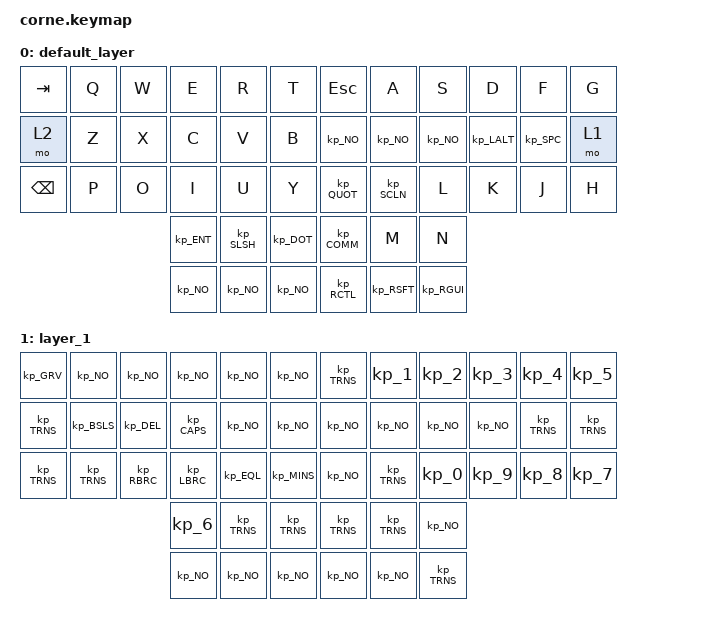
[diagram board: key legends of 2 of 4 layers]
/*
 * Copyright (c) 2020 The ZMK Contributors
 *
 * SPDX-License-Identifier: MIT
 */

#include <behaviors.dtsi>
#include <dt-bindings/zmk/keys.h>
#include <dt-bindings/zmk/bt.h>

/ {
    keymap {
        compatible = "zmk,keymap";

        default_layer {
            bindings = <
                // Layer 0
                &kp TAB &kp Q &kp W &kp E &kp R &kp T      &kp ESC &kp A &kp S &kp D &kp F &kp G
                &mo 2 &kp Z &kp X &kp C &kp V &kp B         &kp_NO &kp_NO &kp_NO &kp_LALT &kp_SPC &mo 1
                &kp BSPC &kp P &kp O &kp I &kp U &kp Y     &kp_QUOT &kp_SCLN &kp L &kp K &kp J &kp H
                &kp_ENT &kp_SLSH &kp_DOT &kp_COMM &kp M &kp N
                &kp_NO &kp_NO &kp_NO &kp_RCTL &kp_RSFT &kp_RGUI
            >;
        };

        layer_1 {
            bindings = <
                // Layer 1
                &kp_GRV &kp_NO &kp_NO &kp_NO &kp_NO &kp_NO
                &kp_TRNS &kp_1 &kp_2 &kp_3 &kp_4 &kp_5
                &kp_TRNS &kp_BSLS &kp_DEL &kp_CAPS &kp_NO &kp_NO
                &kp_NO &kp_NO &kp_NO &kp_NO &kp_TRNS &kp_TRNS
                &kp_TRNS &kp_TRNS &kp_RBRC &kp_LBRC &kp_EQL &kp_MINS
                &kp_NO &kp_TRNS &kp_0 &kp_9 &kp_8 &kp_7
                &kp_6 &kp_TRNS &kp_TRNS &kp_TRNS &kp_TRNS &kp_NO
                &kp_NO &kp_NO &kp_NO &kp_NO &kp_NO &kp_TRNS
            >;
        };

        layer_2 {
            bindings = <
                // Layer 2
                &kp_NO &kp_NO &kp_NO &kp_NO &kp_NO &kp_NO
                &kp_NO &kp_F5 &kp_F6 &kp_F7 &kp_F8 &kp_NO
                &kp_NO &kp_F9 &kp_F10 &kp_F11 &kp_F12 &kp_NO
                &kp_NO &kp_NO &kp_NO &kp_NO &kp_NO &kp_TRNS
                &kp_TRNS &kp_TRNS &kp_HOME &kp_PGUP &kp_NO &kp_NO
                &kp_NO &kp_NO &kp_NO &kp_NO &kp_NO &kp_NO
                &kp_RGHT &kp_UP &kp_DOWN &kp_LEFT &kp_END &kp_F4
                &kp_F3 &kp_F2 &kp_F1 &kp_PGDN &kp_NO &kp_NO
                &kp_NO &kp_TRNS &kp_TRNS &kp_TRNS
            >;
        };

        layer_3 {
            bindings = <
                // Layer 3 (media)
                &kp_NO &kp_NO &kp_NO &kp_NO &kp_NO &kp_NO
                &kp_NO &kp_NO &kp_NO &kp_NO &kp_NO &kp_NO
                &kp_NO &kp_MUTE &kp_MPRV &kp_NO &kp_NO &kp_NO
                &kp_NO &kp_NO &kp_NO &kp_NO &kp_NO &kp_NO
                &kp_MFFD &kp_VOLU &kp_VOLD &kp_MRWD &kp_MPLY &kp_NO
                &kp_NO &kp_NO &kp_NO &kp_NO &kp_MNXT &kp_NO
                &kp_NO &kp_NO &kp_NO &kp_NO &kp_NO &kp_NO
            >;
        };
    };
};
